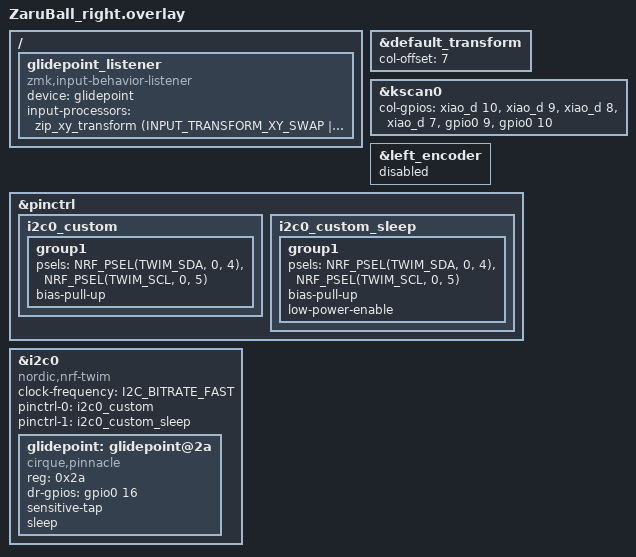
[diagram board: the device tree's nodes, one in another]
#include "ZaruBall.dtsi"
#include <dt-bindings/zmk/input_transform.h>
#include <dt-bindings/pinctrl/nrf-pinctrl.h>

// matrix transformでのピン数オフセット
&default_transform { // Offset of 7 because the left side has 2 columns
    col-offset = <7>;
};

// kscan
&kscan0 {
    col-gpios = 
        <&xiao_d 10 GPIO_ACTIVE_HIGH>,
        <&xiao_d 9 GPIO_ACTIVE_HIGH>,
        <&xiao_d 8 GPIO_ACTIVE_HIGH>,
        <&xiao_d 7 GPIO_ACTIVE_HIGH>,
        <&gpio0 9 GPIO_ACTIVE_HIGH>,
        <&gpio0 10 GPIO_ACTIVE_HIGH>;
};


/* --- ここから追加 --- */
// 右手側ではエンコーダーを無効化する
&left_encoder {
    status = "disabled";
};

&pinctrl {
    /* 起きている時（通信中）のピン設定 */
    i2c0_custom: i2c0_custom {
        group1 {
            psels = <NRF_PSEL(TWIM_SDA, 0, 4)>,
                    <NRF_PSEL(TWIM_SCL, 0, 5)>; 
            bias-pull-up;
        };
    };

    /* 寝ている時（省電力待機中）のピン設定 */
    i2c0_custom_sleep: i2c0_custom_sleep {
        group1 {
            psels = <NRF_PSEL(TWIM_SDA, 0, 4)>,
                    <NRF_PSEL(TWIM_SCL, 0, 5)>;
bias-pull-up;
            low-power-enable; /* スリープさせる命令 */
        };
    };
};

&i2c0 {
    status = "okay";
    compatible = "nordic,nrf-twim";
    clock-frequency = <I2C_BITRATE_FAST>;
    
    /* 上で作った2つの状態をペアで指定します！ */
    pinctrl-0 = <&i2c0_custom>;
    pinctrl-1 = <&i2c0_custom_sleep>;
    pinctrl-names = "default", "sleep";
    
    /* Cirque Pinnacle トラックパッドの設定 */
    glidepoint: glidepoint@2a {
        compatible = "cirque,pinnacle";
        reg = <0x2a>;
        status = "okay";
        
        dr-gpios = <&gpio0 16 (GPIO_ACTIVE_HIGH)>;
        
        sensitive-tap;
        sleep;
    };
};

/* --- シンプルなマウス移動だけのシステム --- */
/ {
    glidepoint_listener: glidepoint_listener {
        compatible = "zmk,input-behavior-listener";
        device = <&glidepoint>;
        status = "okay";

        /* マウスカーソルの移動（向きの調整） */
        input-processors = <
            &zip_xy_transform (INPUT_TRANSFORM_XY_SWAP | INPUT_TRANSFORM_Y_INVERT | INPUT_TRANSFORM_X_INVERT)
        >;
    };
};

